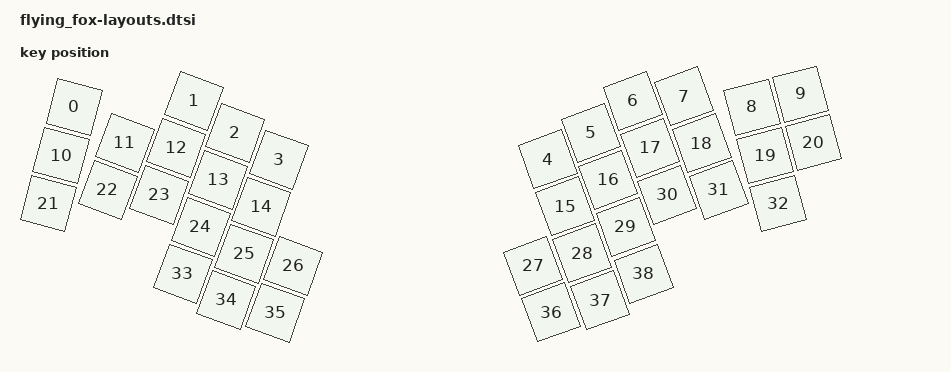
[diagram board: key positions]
#include <physical_layouts.dtsi>

/ {
    physical_layout_flying_fox: physical_layout_flying_fox {
        compatible = "zmk,physical-layout";
        display-name = "Flying Fox";
        keys  //                     w   h    x    y     rot    rx    ry
            = <&key_physical_attrs 100 100(-50)(-12)    1500 (-50) (-12)>
            , <&key_physical_attrs 100 100   47   14    1500    47    14>
            , <&key_physical_attrs 100 100  189(-11)    2000   189 (-11)>
            , <&key_physical_attrs 100 100  292 (-1)    2000   292  (-1)>
            , <&key_physical_attrs 100 100  375   63    2000   375    63>
            , <&key_physical_attrs 100 100  462  116    2000   462   116>
            , <&key_physical_attrs 100 100  965  150   34000   965   150>
            , <&key_physical_attrs 100 100 1052   97   34000  1052    97>
            , <&key_physical_attrs 100 100 1135   33   34000  1135    33>
            , <&key_physical_attrs 100 100 1238   24   34000  1238    24>
            , <&key_physical_attrs 100 100 1377   40   34500  1377    40>
            , <&key_physical_attrs 100 100 1474   14   34500  1474    14>
            , <&key_physical_attrs 100 100(-76)   85    1500 (-76)    85>
            , <&key_physical_attrs 100 100   21  111    1500    21   111>
            , <&key_physical_attrs 100 100  154   83    2000   154    83>
            , <&key_physical_attrs 100 100  257   93    2000   257    93>
            , <&key_physical_attrs 100 100  341  157    2000   341   157>
            , <&key_physical_attrs 100 100  427  210    2000   427   210>
            , <&key_physical_attrs 100 100 1000  244   34000  1000   244>
            , <&key_physical_attrs 100 100 1086  191   34000  1086   191>
            , <&key_physical_attrs 100 100 1170  127   34000  1170   127>
            , <&key_physical_attrs 100 100 1273  118   34000  1273   118>
            , <&key_physical_attrs 100 100 1403  137   34500  1403   137>
            , <&key_physical_attrs 100 100 1500  111   34500  1500   111>
            , <&key_physical_attrs 100 100 (-5)  207    1500  (-5)   207>
            , <&key_physical_attrs 100 100  120  177    2000   120   177>
            , <&key_physical_attrs 100 100  223  187    2000   223   187>
            , <&key_physical_attrs 100 100  306  251    2000   306   251>
            , <&key_physical_attrs 100 100  393  304    2000   393   304>
            , <&key_physical_attrs 100 100  491  329    2000   491   329>
            , <&key_physical_attrs 100 100  936  363   34000   936   363>
            , <&key_physical_attrs 100 100 1034  338   34000  1034   338>
            , <&key_physical_attrs 100 100 1121  285   34000  1121   285>
            , <&key_physical_attrs 100 100 1204  221   34000  1204   221>
            , <&key_physical_attrs 100 100 1307  211   34000  1307   211>
            , <&key_physical_attrs 100 100 1429  233   34500  1429   233>
            , <&key_physical_attrs 100 100  270  344    2000   270   344>
            , <&key_physical_attrs 100 100  357  397    2000   357   397>
            , <&key_physical_attrs 100 100  455  422    2000   455   422>
            , <&key_physical_attrs 100 100  972  456   34000   972   456>
            , <&key_physical_attrs 100 100 1070  432   34000  1070   432>
            , <&key_physical_attrs 100 100 1157  379   34000  1157   379>
            ;
    };
};
